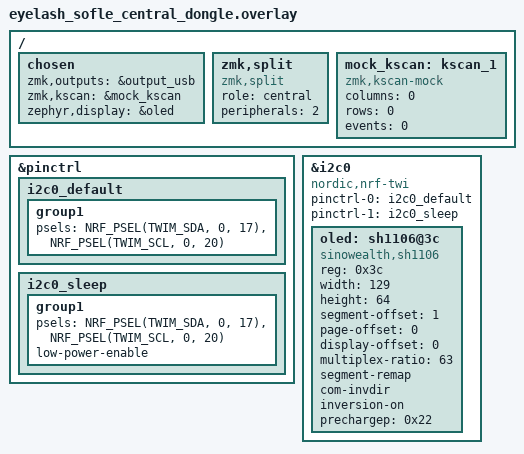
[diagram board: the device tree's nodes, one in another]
/*
 * Dongle central — USB al host; BLE solo para split (2 mitades)
 */

#include "eyelash_sofle.dtsi"

/ {
    chosen {
        /* El host (PC) solo ve USB HID del dongle */
        zmk,outputs = &output_usb;

        /* El dongle no tiene matriz real; mock para satisfacer zmk,kscan */
        zmk,kscan = &mock_kscan;

        /* Usa el OLED definido abajo */
        zephyr,display = &oled;
    };

    /* Split: el dongle actúa como CENTRAL y enlaza 2 periféricos (mitades) */
    zmk,split {
        compatible = "zmk,split";
        role = "central";
        peripherals = <2>;
    };

    /* KSCAN simulado (sin matriz en el dongle) */
    mock_kscan: kscan_1 {
        compatible = "zmk,kscan-mock";
        columns = <0>;
        rows = <0>;
        events = <0>;
    };
};

&pinctrl {
    i2c0_default: i2c0_default {
        group1 {
            psels = <NRF_PSEL(TWIM_SDA, 0, 17)>,
                    <NRF_PSEL(TWIM_SCL, 0, 20)>;
        };
    };

    i2c0_sleep: i2c0_sleep {
        group1 {
            psels = <NRF_PSEL(TWIM_SDA, 0, 17)>,
                    <NRF_PSEL(TWIM_SCL, 0, 20)>;
            low-power-enable;
        };
    };
};

&i2c0 {
    status = "okay";
    compatible = "nordic,nrf-twi";
    pinctrl-0 = <&i2c0_default>;
    pinctrl-1 = <&i2c0_sleep>;

    oled: sh1106@3c {
        compatible = "sinowealth,sh1106";
        reg = <0x3c>;
        width = <129>;
        height = <64>;
        segment-offset = <1>;
        page-offset = <0>;
        display-offset = <0>;
        multiplex-ratio = <63>;
        segment-remap;
        com-invdir;
        inversion-on;
        prechargep = <0x22>;
    };
};
